# H616 register map
Vendor: Allwinner; Series: H616; File version: 0.1
CPU: other 0, little endian, MPU, no FPU, 0 interrupt priority bits
Registers are 32-bit, read-write, reset 0x0 unless marked. A register's access mark holds for its fields unless they carry their own. Offsets are from the block's base; [hi:lo] are bit positions; {n}, {i} and the like mark numbered series.

## Thermal_Sensor
Base 0x05070400
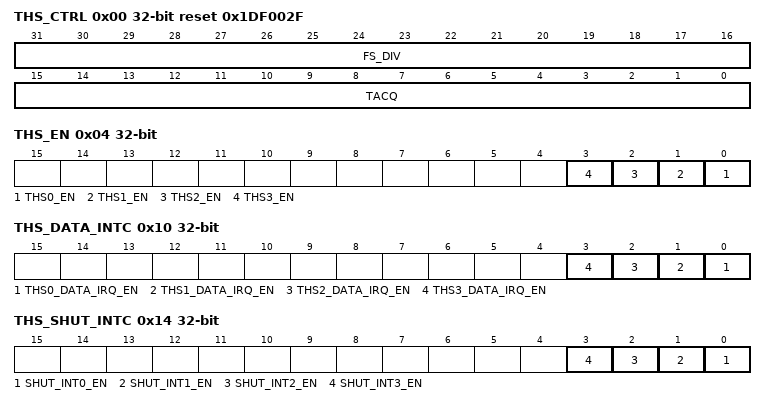
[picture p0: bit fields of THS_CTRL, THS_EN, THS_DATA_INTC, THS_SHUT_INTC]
0x00 THS_CTRL reset 0x1DF002F — THS Control Register
  [31:16] FS_DIV — ADC Sample Frequency Divider CLK_IN/(N+1) , N > 0x17 The default value indicates 50 kHz.
  [15:0] TACQ — ADC Acquire Time CLK_IN/(n+1) The default value indicates 2us.
0x04 THS_EN — THS Enable Register
  [n] THS{n}_EN (n=0..3) — Enable temperature measurement sensor{n} 0:Disable 1:Enable
0x08 THS_PER reset 0x3A000 — THS Period Control Register
  [31:12] THERMAL_PER — 4096*(n+1)/CLK_IN The default value indicates 10ms.
0x10 THS_DATA_INTC — THS Data Interrupt Control Register
  [n] THS{n}_DATA_IRQ_EN (n=0..3) — Selects temperature measurement data of sensor{n} 0:Disable 1:Enable
0x14 THS_SHUT_INTC — THS Shut Interrupt Control Register
  [n] SHUT_INT{n}_EN (n=0..3) — Selects shutdown interrupt for sensor{n} 0:Disable 1:Enable
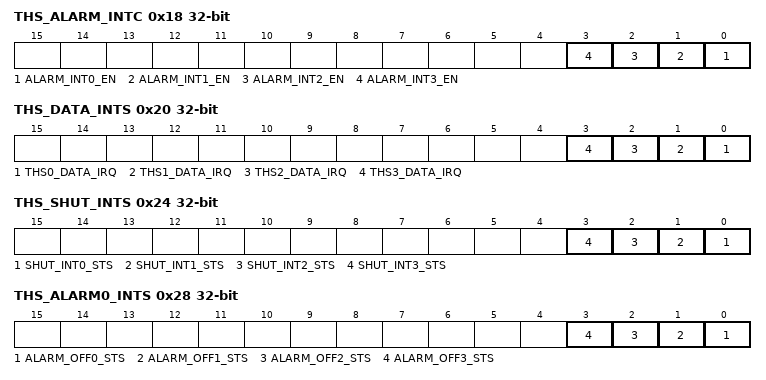
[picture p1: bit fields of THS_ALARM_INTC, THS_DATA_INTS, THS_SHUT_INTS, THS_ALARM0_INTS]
0x18 THS_ALARM_INTC — THS Alarm Interrupt Control Register
  [n] ALARM_INT{n}_EN (n=0..3) — Selects alarm interrupt for sensor{n} 0:Disable 1:Enable
0x20 THS_DATA_INTS — THS Data Interrupt Status Register
  [n] THS{n}_DATA_IRQ write-1-clears (n=0..3) — _STS Data interrupt status for sensor{n} Write `1` to clear this interrupt.
0x24 THS_SHUT_INTS — THS Shut Interrupt Status Register
  [n] SHUT_INT{n}_STS write-1-clears (n=0..3) — Shutdown interrupt status for sensor{n} Write `1` to clear this interrupt.
0x28 THS_ALARM0_INTS
  [n] ALARM_OFF{n}_STS write-1-clears (n=0..3) — Alarm interrupt off pending for sensor{n} Write `1` to clear this interrupt.
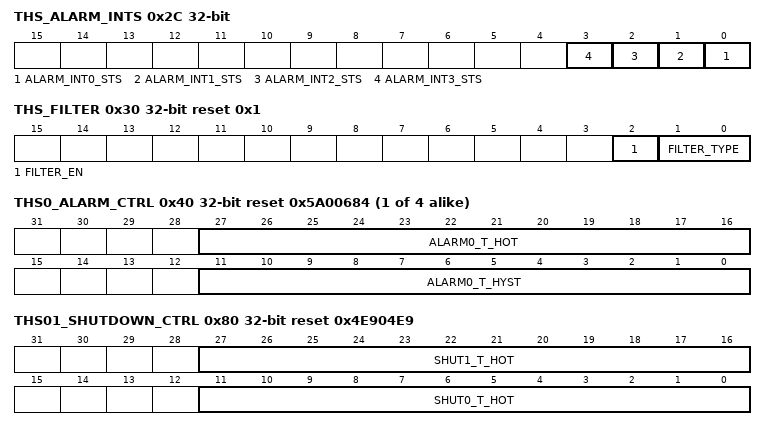
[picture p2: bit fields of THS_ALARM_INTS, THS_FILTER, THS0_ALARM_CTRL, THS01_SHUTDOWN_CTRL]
0x2C THS_ALARM_INTS — THS Alarm Interrupt Status Register
  [n] ALARM_INT{n}_STS write-1-clears (n=0..3) — Alarm interrupt pending for sensor{n} Write `1` to clear this interrupt.
0x30 THS_FILTER reset 0x1 — THS Median Filter Control Register
  [2] FILTER_EN — Filter Enable 0: Disable 1: Enable
    0=Disable; 1=Enable
  [1:0] FILTER_TYPE — Average Filter Type 00: 2 01: 4 10: 8 11: 16
    0=_2; 1=_4; 2=_8; 3=_16
{0x40+4i} THS{i}_ALARM_CTRL reset 0x5A00684 (i=0..3) — THS{i} Alarm Threshold Control Register
  [27:16] ALARM{i}_T_HOT — Thermal Sensor{i} alarm threshold for hot temperature
  [11:0] ALARM{i}_T_HYST — Thermal Sensor{i} alarm threshold for hysteresis temperature
0x80 THS01_SHUTDOWN_CTRL reset 0x4E904E9 — THS0 & THS1 Shutdown Threshold Control Register
  [27:16] SHUT1_T_HOT — Thermal Sensor1 shutdown threshold for hot temperature
  [11:0] SHUT0_T_HOT — Thermal Sensor0 shutdown threshold for hot temperature
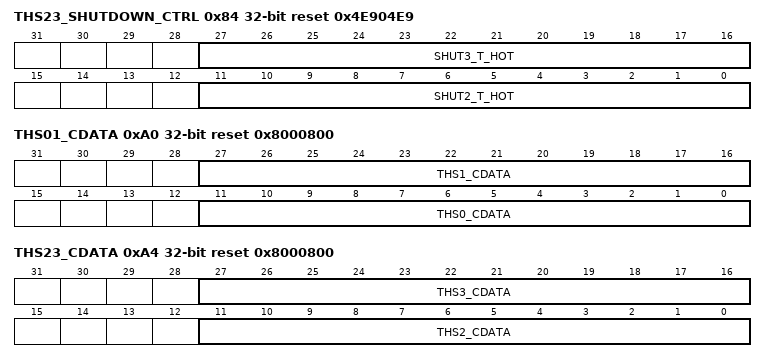
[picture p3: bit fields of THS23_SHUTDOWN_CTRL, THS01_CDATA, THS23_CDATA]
0x84 THS23_SHUTDOWN_CTRL reset 0x4E904E9 — THS2 & THS3 Shutdown Threshold Control Register
  [27:16] SHUT3_T_HOT — Thermal Sensor3 shutdown threshold for hot temperature
  [11:0] SHUT2_T_HOT — Thermal Sensor2 shutdown threshold for hot temperature
0xA0 THS01_CDATA reset 0x8000800 — THS0 & THS1 Calibration Data
  [27:16] THS1_CDATA — Thermal Sensor1 calibration data
  [11:0] THS0_CDATA — Thermal Sensor0 calibration data
0xA4 THS23_CDATA reset 0x8000800 — THS2 & THS3 Calibration Data
  [27:16] THS3_CDATA — Thermal Sensor3 calibration data
  [11:0] THS2_CDATA — Thermal Sensor2 calibration data
{0xC0+4i} THS{i}_DATA (i=0..3)
  [11:0] THS{i}_DATA ro — Temperature measurement data of sensor{i}

## TVE_TOP
Base 0x06520000
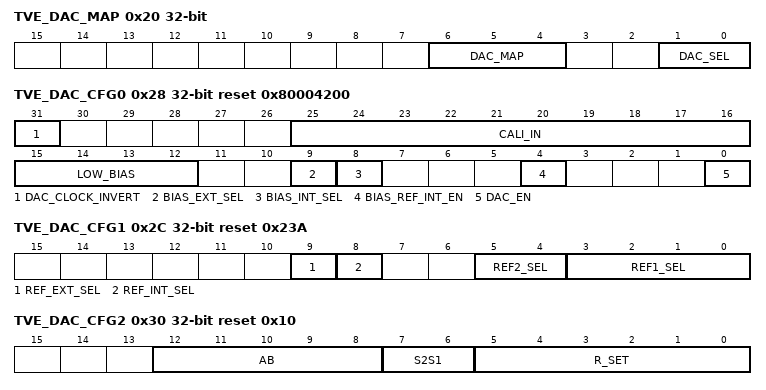
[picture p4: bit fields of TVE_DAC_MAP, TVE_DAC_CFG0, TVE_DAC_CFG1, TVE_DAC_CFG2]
0x20 TVE_DAC_MAP — TV Encoder DAC MAP Register
  [6:4] DAC_MAP — 000: OUT0 Others: Reserved
    0=OUT0 (OUT0 Others: Reserved)
  [1:0] DAC_SEL — 00: Reserved 01: TVE0 10: Reserved 11: Reserved
    1=TVE0
0x24 TVE_DAC_STATUS — TV Encoder DAC STAUTS Register
  [1:0] DAC_STATUS — 00: Unconnected 01: Connected 11: Short to ground 10: Reserved
    0=Unconnected; 1=Connected; 3=Short to ground
0x28 TVE_DAC_CFG0 reset 0x80004200 — TV Encoder DAC CFG0 Register
  [31] DAC_CLOCK_INVERT — 0: Not invert 1: Invert
    0=Not_invert; 1=Invert
  [25:16] CALI_IN
  [15:12] LOW_BIAS — 500uA to 4mA
  [9] BIAS_EXT_SEL — 0: disable 1: enable (A_SEL_BIAS_ADDA)
    0=disable; 1=enable (A_SEL_BIAS_ADDA)
  [8] BIAS_INT_SEL — 0: disable 1: enable (A_SEL_BIAS_RES)
    0=disable; 1=enable (A_SEL_BIAS_RES)
  [4] BIAS_REF_INT_EN — 0: disable 1: enable (A_EN_RESREF)
    0=disable; 1=enable (A_EN_RESREF)
  [0] DAC_EN — 0: Disable 1: Enable
    0=Disable; 1=Enable
0x2C TVE_DAC_CFG1 reset 0x23A — TV Encoder DAC CFG1 Register
  [9] REF_EXT_SEL — 0: disable 1: enable (A_SEL_DETREF_LDO)
    0=disable; 1=enable (A_SEL_DETREF_LDO)
  [8] REF_INT_SEL — 0: disable 1: enable (A_SEL_DETREF_RES)
    0=disable; 1=enable (A_SEL_DETREF_RES)
  [5:4] REF2_SEL — 00: 0.25V 01: 0.30V 10: 0.35V 11: 0.40V (a_refslct2<1:0>)
    0=_0_point_25V (0.25V); 1=_0_point_30V (0.30V); 2=_0_point_35V (0.35V); 3=_0_point_40V (0.40V (a_refslct2<1:0>))
  [3:0] REF1_SEL — 0000: 0.50V 0001: 0.55V 0010: 0.60V 0011: 0.65V 0100: 0.70V 0101: 0.75V 0110: 0.80V 0111: 0.85V 1000: 0.90V 1001: 0.95V 1010: 1.00V 1011: 1.05V 1100: 1.10V 1101: 1.15V 1110: 1.20V 1111: 1.25V (a_refslct1<3:0>) The reference voltage is used for hot plug detect function.
    0=_0_point_50V (0.50V); 1=_0_point_55V (0.55V); 2=_0_point_60V (0.60V); 3=_0_point_65V (0.65V); 4=_0_point_70V (0.70V); 5=_0_point_75V (0.75V); 6=_0_point_80V (0.80V); 7=_0_point_85V (0.85V); 8=_0_point_90V (0.90V); 9=_0_point_95V (0.95V); 10=_1_point_00V (1.00V); 11=_1_point_05V (1.05V); 12=_1_point_10V (1.10V); 13=_1_point_15V (1.15V); 14=_1_point_20V (1.20V); 15=_1_point_25V (1.25V (a_refslct1<3:0>) The reference voltage is used for hot plug detect function.)
0x30 TVE_DAC_CFG2 reset 0x10 — TV Encoder DAC CFG2 Register
  [12:8] AB — ( I config output current for different peak voltage)
  [7:6] S2S1
  [5:0] R_SET
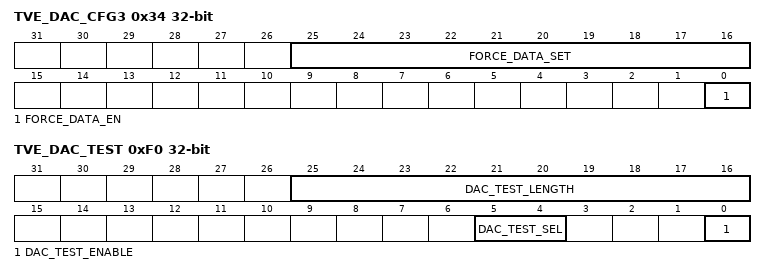
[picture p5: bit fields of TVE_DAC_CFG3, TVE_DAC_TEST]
0x34 TVE_DAC_CFG3 — TV Encoder DAC CFG2 Register
  [25:16] FORCE_DATA_SET — Force DAC input data
  [0] FORCE_DATA_EN — 0:DAC input data from TVE 1: DAC input data from FORCE_DATA_SET
    1=DAC (DAC input data from FORCE_DATA_SET)
0xF0 TVE_DAC_TEST — TV Encoder DAC TEST Register
  [25:16] DAC_TEST_LENGTH — DAC TEST DATA LENGTH
  [5:4] DAC_TEST_SEL — 00: DAC0 Others:Reserved
    0=DAC0 (DAC0 Others:Reserved)
  [0] DAC_TEST_ENABLE — 0: Reserved 1: Repeat DAC data from DAC sram
    1=Repeat DAC data from DAC sram
